# nrf54l15_enga_flpr register map
Vendor: Nordic Semiconductor; Series: nrf54l; File version: 1
Registers are 32-bit, read-write, reset 0x0 unless marked. A register's access mark holds for its fields unless they carry their own. Offsets are from the block's base; [hi:lo] are bit positions; {n}, {i} and the like mark numbered series; 'fields as' and 'values as' point back to an identical list.

## GLOBAL_CRACEN_S — CRACEN
Base 0x50048000
0x100 EVENTS_CRYPTOMASTER — Event indicating that interrupt triggered at Cryptomaster
  [0] EVENTS_CRYPTOMASTER
    0=NotGenerated (Event not generated); 1=Generated (Event generated)
0x104 EVENTS_RNG — Event indicating that interrupt triggered at RNG
  [0] EVENTS_RNG
    values as EVENTS_CRYPTOMASTER.EVENTS_CRYPTOMASTER
0x108 EVENTS_PKEIKG — Event indicating that interrupt triggered at PKE or IKG
  [0] EVENTS_PKEIKG
    values as EVENTS_CRYPTOMASTER.EVENTS_CRYPTOMASTER
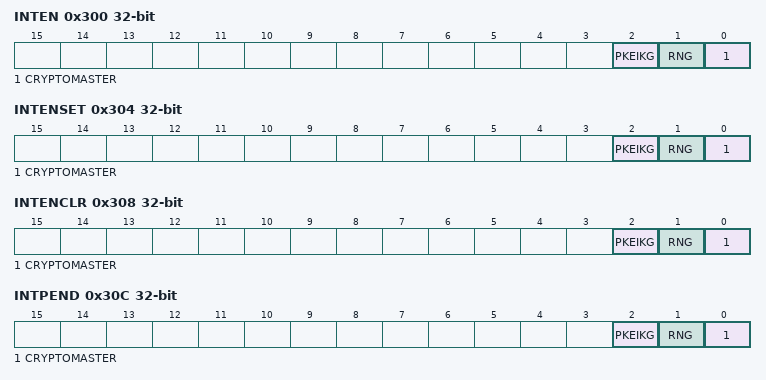
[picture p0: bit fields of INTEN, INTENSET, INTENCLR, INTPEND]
0x300 INTEN — Enable or disable interrupt
  [all] fields
    0=Disabled; 1=Enabled
  [2] PKEIKG — Enable or disable interrupt for event PKEIKG
  [1] RNG — Enable or disable interrupt for event RNG
  [0] CRYPTOMASTER — Enable or disable interrupt for event CRYPTOMASTER
0x304 INTENSET — Enable interrupt
  [all] fields
    on read: 0=Disabled (Read: Disabled); 1=Enabled (Read: Enabled) | on write: 1=Set (Enable)
  [2] PKEIKG — Write '1' to enable interrupt for event PKEIKG
  [1] RNG — Write '1' to enable interrupt for event RNG
  [0] CRYPTOMASTER — Write '1' to enable interrupt for event CRYPTOMASTER
0x308 INTENCLR — Disable interrupt
  [all] fields
    on read: 0=Disabled (Read: Disabled); 1=Enabled (Read: Enabled) | on write: 1=Clear (Disable)
  [2] PKEIKG — Write '1' to disable interrupt for event PKEIKG
  [1] RNG — Write '1' to disable interrupt for event RNG
  [0] CRYPTOMASTER — Write '1' to disable interrupt for event CRYPTOMASTER
0x30C INTPEND ro — Pending interrupts
  [all] fields
    on read: 0=NotPending (Read: Not pending); 1=Pending (Read: Pending)
  [2] PKEIKG — Read pending status of interrupt for event PKEIKG
  [1] RNG — Read pending status of interrupt for event RNG
  [0] CRYPTOMASTER — Read pending status of interrupt for event CRYPTOMASTER
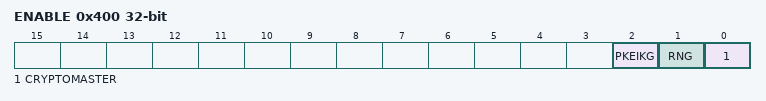
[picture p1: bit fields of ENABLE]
0x400 ENABLE — Enable CRACEN peripheral modules.
  [2] PKEIKG — Enable PKE and IKG
    0=Disabled (PKE and IKG disabled.); 1=Enabled (PKE and IKG enabled.)
  [1] RNG — Enable RNG
    0=Disabled (RNG disabled.); 1=Enabled (RNG enabled.)
  [0] CRYPTOMASTER — Enable cryptomaster
    0=Disabled (Cryptomaster disabled.); 1=Enabled (Cryptomaster enabled.)
0x404 PROTECTEDRAMLOCK — Lock the access to the protected RAM.
  [0] ENABLE — Enable the lock
    0=Disabled (Lock disabled.); 1=Enabled (Lock enabled.)
0x404 SEEDRAMLOCK (alternate view of PROTECTEDRAMLOCK) — Lock the access to the RAM used for the seed.
  fields as PROTECTEDRAMLOCK
{0x408+4i} SEED[{i}] (i=0..11) wo — Description collection: Seed word [n] for symmetric and asymmetric key generation. This register is only writable from KMU.
  [31:0] VAL — Seed value

## GLOBAL_GLITCHDET_S — Voltage glitch detectors
Base 0x5004B000
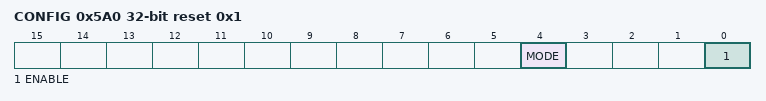
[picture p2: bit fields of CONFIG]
0x5A0 CONFIG reset 0x1 — Configuration for glitch detector
  [4] MODE — Glitch detector mode
    0=High pass filter mode; 1=Cap divider mode
  [0] ENABLE — Enable glitch detector
    0=Disable glitch detector; 1=Enable glitch detector

## GLOBAL_P2_NS — GPIO Port 0
Base 0x40050400
Same registers: GLOBAL_P1_NS 0x400D8200, GLOBAL_P0_NS 0x4010A000, GLOBAL_P2_S 0x50050400, GLOBAL_P1_S 0x500D8200, GLOBAL_P0_S 0x5010A000
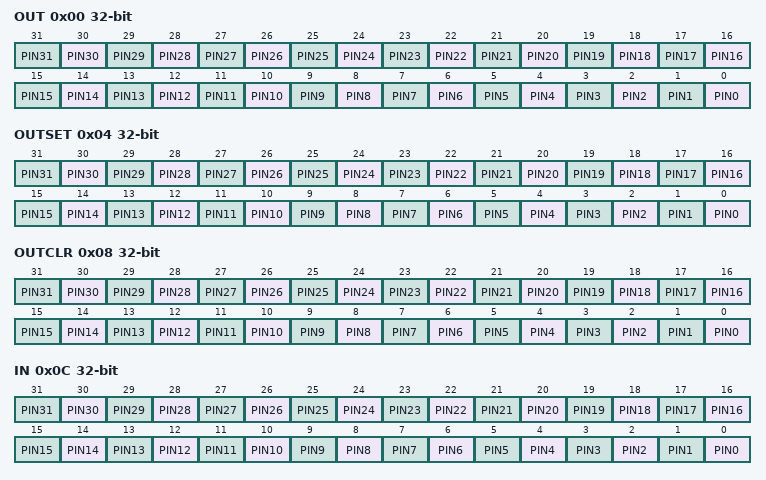
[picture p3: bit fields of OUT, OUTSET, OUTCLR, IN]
0x00 OUT — Write GPIO port
  [all] fields
    0=Low (Pin driver is low); 1=High (Pin driver is high)
  [n] PIN{n} (n=0..31)
0x04 OUTSET write-1-sets — Set individual bits in GPIO port
  [all] fields
    on read: 0=Low (Read: pin driver is low); 1=High (Read: pin driver is high) | on write: 1=Set (Write: writing a '1' sets the pin high; writing a '0' has no effect)
  [n] PIN{n} (n=0..31)
0x08 OUTCLR write-1-clears — Clear individual bits in GPIO port
  [all] fields
    on read: 0=Low (Read: pin driver is low); 1=High (Read: pin driver is high) | on write: 1=Clear (Write: writing a '1' sets the pin low; writing a '0' has no effect)
  [n] PIN{n} (n=0..31)
0x0C IN ro — Read GPIO port
  [all] fields
    0=Low (Pin input is low); 1=High (Pin input is high)
  [n] PIN{n} (n=0..31)
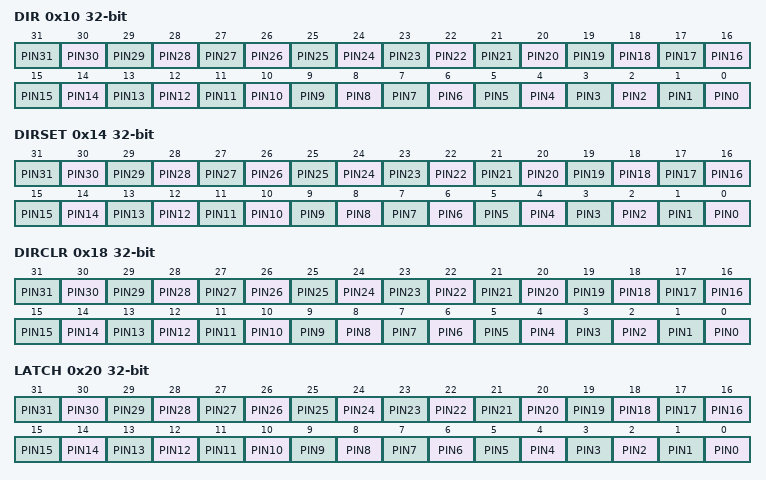
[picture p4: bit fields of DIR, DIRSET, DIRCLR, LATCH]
0x10 DIR — Direction of GPIO pins
  [all] fields
    0=Input (Pin set as input); 1=Output (Pin set as output)
  [n] PIN{n} (n=0..31)
0x14 DIRSET write-1-sets
  [all] fields
    on read: 0=Input (Read: pin set as input); 1=Output (Read: pin set as output) | on write: 1=Set (Write: writing a '1' sets pin to output; writing a '0' has no effect)
  [n] PIN{n} (n=0..31) — Set as output pin {n}
0x18 DIRCLR write-1-clears — DIR clear register
  [all] fields
    on read: 0=Input (Read: pin set as input); 1=Output (Read: pin set as output) | on write: 1=Clear (Write: writing a '1' sets pin to input; writing a '0' has no effect)
  [n] PIN{n} (n=0..31) — Set as input pin {n}
0x20 LATCH — Latch register indicating what GPIO pins that have met the criteria set in the PIN_CNF[n].SENSE registers
  [all] fields
    0=NotLatched (Criteria has not been met); 1=Latched (Criteria has been met)
  [n] PIN{n} (n=0..31) — Status on whether PIN{n} has met criteria set in PIN_CNF[{n}].SENSE register. Write '1' to clear.
0x24 DETECTMODE — Select between default DETECT signal behavior and LDETECT mode
  [0] DETECTMODE
    0=Default (DETECT directly connected to PIN DETECT signals); 1=LDETECT (Use the latched LDETECT behavior)
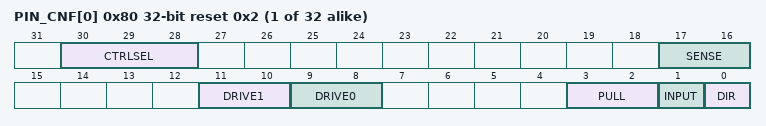
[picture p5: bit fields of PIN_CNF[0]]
{0x80+4i} PIN_CNF[{i}] (i=0..31) reset 0x2 — Description collection: Pin n configuration of GPIO pin
  [30:28] CTRLSEL — Select which module has direct control over this pin
    0=GPIO (GPIO or peripherals with PSEL registers); 1=VPR (VPR processor); 4=GRTC (GRTC peripheral); 7=TND (Trace and Debug Subsystem)
  [17:16] SENSE — Pin sensing mechanism
    0=Disabled; 2=High (Sense for high level); 3=Low (Sense for low level)
  [11:10] DRIVE1 — Drive configuration for '1'
    0=S1 (Standard '1'); 1=H1 (High drive '1'); 2=D1 (Disconnect '1'(normally used for wired-or connections)); 3=E1 (Extra high drive '1')
  [9:8] DRIVE0 — Drive configuration for '0'
    0=S0 (Standard '0'); 1=H0 (High drive '0'); 2=D0 (Disconnect '0'(normally used for wired-or connections)); 3=E0 (Extra high drive '0')
  [3:2] PULL — Pull configuration
    0=Disabled (No pull); 1=Pull down on pin; 3=Pull up on pin
  [1] INPUT — Connect or disconnect input buffer
    0=Connect input buffer; 1=Disconnect input buffer
  [0] DIR — Pin direction. Same physical register as DIR register
    0=Input (Configure pin as an input pin); 1=Output (Configure pin as an output pin)

## Notices in the file
Copyright (c) 2010 - 2024, Nordic Semiconductor ASA All rights reserved.
SPDX-License-Identifier: BSD-3-Clause
Redistribution and use in source and binary forms, with or without
modification, are permitted provided that the following conditions are met:
1. Redistributions of source code must retain the above copyright notice, this
list of conditions and the following disclaimer.
2. Redistributions in binary form must reproduce the above copyright
notice, this list of conditions and the following disclaimer in the
documentation and/or other materials provided with the distribution.
3. Neither the name of Nordic Semiconductor ASA nor the names of its
contributors may be used to endorse or promote products derived from this
software without specific prior written permission.
THIS SOFTWARE IS PROVIDED BY THE COPYRIGHT HOLDERS AND CONTRIBUTORS "AS IS"
AND ANY EXPRESS OR IMPLIED WARRANTIES, INCLUDING, BUT NOT LIMITED TO, THE
IMPLIED WARRANTIES OF MERCHANTABILITY, AND FITNESS FOR A PARTICULAR PURPOSE
ARE DISCLAIMED. IN NO EVENT SHALL NORDIC SEMICONDUCTOR ASA OR CONTRIBUTORS BE
LIABLE FOR ANY DIRECT, INDIRECT, INCIDENTAL, SPECIAL, EXEMPLARY, OR
CONSEQUENTIAL DAMAGES (INCLUDING, BUT NOT LIMITED TO, PROCUREMENT OF
SUBSTITUTE GOODS OR SERVICES; LOSS OF USE, DATA, OR PROFITS; OR BUSINESS
INTERRUPTION) HOWEVER CAUSED AND ON ANY THEORY OF LIABILITY, WHETHER IN
CONTRACT, STRICT LIABILITY, OR TORT (INCLUDING NEGLIGENCE OR OTHERWISE)
ARISING IN ANY WAY OUT OF THE USE OF THIS SOFTWARE, EVEN IF ADVISED OF THE
POSSIBILITY OF SUCH DAMAGE.
